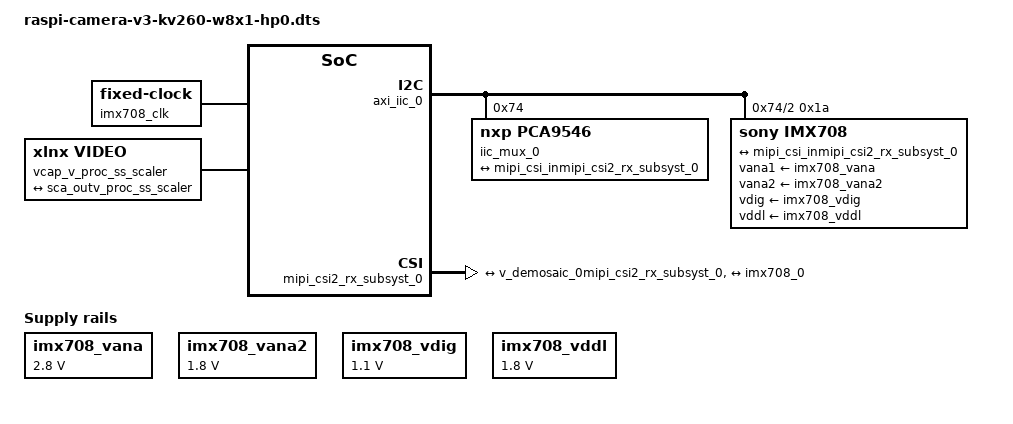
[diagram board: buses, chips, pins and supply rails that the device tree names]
/*
 * CAUTION: This file is automatically generated by Xilinx.
 * Version: XSCT 2022.1
 * Today is: Thu Jul 28 16:23:50 2022
 */


/dts-v1/;
/plugin/;
/ {
	fragment@0 {
		target = <&fpga_full>;
		overlay0: __overlay__ {
			#address-cells = <2>;
			#size-cells = <2>;
			firmware-name = "raspi-camera-v3-kv260-w8x1-hp0.bin";
			resets = <&zynqmp_reset 116>;
		};
	};
	fragment@1 {
		target = <&amba>;
		overlay1: __overlay__ {
			afi0: afi0 {
				compatible = "xlnx,afi-fpga";
				config-afi = < 0 0>, <1 0>, <2 0>, <3 0>, <4 0>, <5 0>, <6 0>, <7 0>, <8 0>, <9 0>, <10 0>, <11 0>, <12 0>, <13 0>, <14 0xa00>, <15 0x000>;
			};
			clocking0: clocking0 {
				#clock-cells = <0>;
				assigned-clock-rates = <99999001>;
				assigned-clocks = <&zynqmp_clk 71>;
				clock-output-names = "fabric_clk";
				clocks = <&zynqmp_clk 71>;
				compatible = "xlnx,fclk";
			};
			clocking1: clocking1 {
				#clock-cells = <0>;
				assigned-clock-rates = <99999001>;
				assigned-clocks = <&zynqmp_clk 72>;
				clock-output-names = "fabric_clk";
				clocks = <&zynqmp_clk 72>;
				compatible = "xlnx,fclk";
			};
		};
	};
	fragment@2 {
		target-path="/";
		overlay2: __overlay__ {
			imx708_vana: fixedregulator0 {
				compatible = "regulator-fixed";
				regulator-name = "imx708_vana";
				regulator-min-microvolt = <2800000>;
				regulator-max-microvolt = <2800000>;
			};
			imx708_vana2: fixedregulator1 {
				compatible = "regulator-fixed";
				regulator-name = "imx708_vana2";
				regulator-min-microvolt = <1800000>;
				regulator-max-microvolt = <1800000>;
			};
			imx708_vdig: fixedregulator2 {
				compatible = "regulator-fixed";
				regulator-name = "imx708_vdig";
				regulator-min-microvolt = <1100000>;
				regulator-max-microvolt = <1100000>;
			};
			imx708_vddl: fixedregulator3 {
				compatible = "regulator-fixed";
				regulator-name = "imx708_vddl";
				regulator-min-microvolt = <1800000>;
				regulator-max-microvolt = <1800000>;
			};
			imx708_clk:camera-clk {
				compatible = "fixed-clock";
				#clock-cells = <0>;
				clock-frequency = <24000000>;
			};
		};
	};
	fragment@3 {
		target = <&amba>;
		overlay3: __overlay__ {
			#address-cells = <2>;
			#size-cells = <2>;
			axi_iic_0: i2c@80030000 {
				#address-cells = <1>;
				#size-cells = <0>;
				clock-names = "s_axi_aclk";
				clocks = <&misc_clk_0>;
				compatible = "xlnx,axi-iic-2.1", "xlnx,xps-iic-2.00.a";
				interrupt-names = "iic2intc_irpt";
				interrupt-parent = <&gic>;
				interrupts = <0 104 4>;
				reg = <0x0 0x80030000 0x0 0x10000>;
				iic_mux_0: i2c_mux@74 { /* u18 */
					compatible = "nxp,pca9546";
					#address-cells = <1>;
					#size-cells = <0>;
					reg = <0x74>;
					isa0_i2c0: i2c@0 {
						reg = <0>;
					};
					isa1_i2c1: i2c@1 {
						reg = <1>;
					};
					rpi_i2c2: i2c@2 {
						#address-cells = <1>;
						#size-cells = <0>;
						reg = <2>;
						imx708: sensor@1a {
							compatible = "sony,imx708";
							reg = <0x1a>;
							clocks = <&imx708_clk>;
							vana1-supply = <&imx708_vana>;   /* 2.8v */
							vana2-supply = <&imx708_vana2>;   /* 1.8v */
							vdig-supply = <&imx708_vdig>;   /* 1.1v */
							vddl-supply = <&imx708_vddl>;   /* 1.8v */
							port {
								imx708_0: endpoint {
									remote-endpoint = <&mipi_csi_inmipi_csi2_rx_subsyst_0>;
									data-lanes = <1 2>;
									clock-noncontinuous;
									link-frequencies = /bits/ 64 <450000000>;
				   				};
							};
						};
					};
				/* Bus 4/4 are not connected */
				};
			};
			misc_clk_0: misc_clk_0 {
				#clock-cells = <0>;
				clock-frequency = <99999000>;
				compatible = "fixed-clock";
			};
			mipi_csi2_rx_subsyst_0: mipi_csi2_rx_subsystem@80002000 {
				clock-names = "dphy_clk_200M", "lite_aclk", "video_aclk";
				clocks = <&misc_clk_1>, <&misc_clk_0>, <&misc_clk_1>;
				compatible = "xlnx,mipi-csi2-rx-subsystem-5.4", "xlnx,mipi-csi2-rx-subsystem-5.0";
				interrupt-names = "csirxss_csi_irq";
				interrupt-parent = <&gic>;
				interrupts = <0 105 4>;
				reg = <0x0 0x80002000 0x0 0x2000>;
				xlnx,axis-tdata-width = <32>;
				xlnx,csi-pxl-format = <0x2b>;
				xlnx,max-lanes = <2>;
				xlnx,ppc = <1>;
				xlnx,vc = <4>;
				xlnx,vfb;
				mipi_csi_portsmipi_csi2_rx_subsyst_0: ports {
					#address-cells = <1>;
					#size-cells = <0>;
					mipi_csi_port1mipi_csi2_rx_subsyst_0: port@1 {
						reg = <1>;
						mipi_csirx_outmipi_csi2_rx_subsyst_0: endpoint {
							remote-endpoint = <&v_demosaic_0mipi_csi2_rx_subsyst_0>;
						};
					};
					mipi_csi_port0mipi_csi2_rx_subsyst_0: port@0 {
						/* User need to add something like remote-endpoint=<&out> under the node csiss_in:endpoint */
						reg = <0>;
						mipi_csi_inmipi_csi2_rx_subsyst_0: endpoint {
							remote-endpoint = <&imx708_0>;
							data-lanes = <1 2>;
						};
					};
				};
			};
			misc_clk_1: misc_clk_1 {
				#clock-cells = <0>;
				clock-frequency = <199998000>;
				compatible = "fixed-clock";
			};
			v_demosaic_0: v_demosaic@a0010000 {
				clock-names = "ap_clk";
				clocks = <&misc_clk_1>;
				compatible = "xlnx,v-demosaic-1.1", "xlnx,v-demosaic";
				interrupt-names = "interrupt";
				interrupt-parent = <&gic>;
				interrupts = <0 106 4>;
				reg = <0x0 0xa0010000 0x0 0x10000>;
				reset-gpios = <&gpio 78 1>;
				xlnx,max-height = <4320>;
				xlnx,max-width = <8192>;
				xlnx,s-axi-ctrl-addr-width = <0x6>;
				xlnx,s-axi-ctrl-data-width = <0x20>;
				demosaic_portsv_demosaic_0: ports {
					#address-cells = <1>;
					#size-cells = <0>;
					demosaic_port1v_demosaic_0: port@1 {
						reg = <1>;
						demo_outv_demosaic_0: endpoint {
							remote-endpoint = <&v_proc_ss_cscv_demosaic_0>;
						};
					};
					demosaic_port0v_demosaic_0: port@0 {
						reg = <0>;
						v_demosaic_0mipi_csi2_rx_subsyst_0: endpoint {
							remote-endpoint = <&mipi_csirx_outmipi_csi2_rx_subsyst_0>;
						};
					};
				};
			};
			v_frmbuf_wr_0: v_frmbuf_wr@a0020000 {
				#dma-cells = <1>;
				clock-names = "ap_clk";
				clocks = <&misc_clk_1>;
				compatible = "xlnx,v-frmbuf-wr-2.5", "xlnx,axi-frmbuf-wr-v2.2";
				interrupt-names = "interrupt";
				interrupt-parent = <&gic>;
				interrupts = <0 108 4>;
				reg = <0x0 0xa0020000 0x0 0x10000>;
				reset-gpios = <&gpio 82 1>;
				xlnx,dma-addr-width = <32>;
				xlnx,dma-align = <8>;
				xlnx,max-height = <4320>;
				xlnx,max-width = <8192>;
				xlnx,pixels-per-clock = <1>;
				xlnx,s-axi-ctrl-addr-width = <0x7>;
				xlnx,s-axi-ctrl-data-width = <0x20>;
				xlnx,vid-formats = "rgb888", "bgr888", "xbgr8888", "xrgb8888", "vuy888", "xvuy8888", "nv12";
				xlnx,video-width = <8>;
			};
			v_gamma_lut_0: v_gamma_lut@a0030000 {
				clock-names = "ap_clk";
				clocks = <&misc_clk_1>;
				compatible = "xlnx,v-gamma-lut-1.1", "xlnx,v-gamma-lut";
				interrupt-names = "interrupt";
				interrupt-parent = <&gic>;
				interrupts = <0 107 4>;
				reg = <0x0 0xa0030000 0x0 0x10000>;
				reset-gpios = <&gpio 79 1>;
				xlnx,max-height = <4320>;
				xlnx,max-width = <8192>;
				xlnx,s-axi-ctrl-addr-width = <13>;
				xlnx,s-axi-ctrl-data-width = <32>;
				gamma_portsv_gamma_lut_0: ports {
					#address-cells = <1>;
					#size-cells = <0>;
					gamma_port1v_gamma_lut_0: port@1 {
						reg = <1>;
						xlnx,video-width  = <10>;
						gamma_outv_gamma_lut_0: endpoint {
							remote-endpoint = <&v_proc_ss_scalerv_gamma_lut_0>;
						};
					};
					gamma_port0v_gamma_lut_0: port@0 {
						reg = <0>;
						xlnx,video-width  = <10>;
						v_gamma_lut_0v_proc_ss_csc: endpoint {
							remote-endpoint = <&csc_outv_proc_ss_csc>;
						};
					};
				};
			};
			v_proc_ss_csc: v_proc_ss_csc@a0040000 {
				clock-names = "aclk";
				clocks = <&misc_clk_1>;
				compatible = "xlnx,v-vpss-csc";
				reg = <0x0 0xa0040000 0x0 0x10000>;
				reset-gpios = <&gpio 80 1>;
				xlnx,colorspace-support = <0>;
				xlnx,csc-enable-window = "true";
				xlnx,max-height = <4320>;
				xlnx,max-width = <8192>;
				xlnx,num-video-components = <3>;
				xlnx,samples-per-clk = <1>;
				xlnx,topology = <3>;
				xlnx,use-uram = <0>;
				xlnx,video-width = <10>;
				csc_portsv_proc_ss_csc: ports {
					#address-cells = <1>;
					#size-cells = <0>;
					csc_port1v_proc_ss_csc: port@1 {
				        /* For xlnx,video-format user needs to fill as per their requirement */
						reg = <1>;
						xlnx,video-format = <3>;
						xlnx,video-width  = <10>;
						csc_outv_proc_ss_csc: endpoint {
							remote-endpoint = <&v_gamma_lut_0v_proc_ss_csc>;
						};
					};
					csc_port0v_proc_ss_csc: port@0 {
				        /* For xlnx,video-format user needs to fill as per their requirement */
						reg = <0>;
						xlnx,video-format = <3>;
						xlnx,video-width  = <10>;
						v_proc_ss_cscv_demosaic_0: endpoint {
							remote-endpoint = <&demo_outv_demosaic_0>;
						};
					};
				};
			};
			v_proc_ss_scaler: v_proc_ss_scaler@a0080000 {
				clock-names = "aclk_axis", "aclk_ctrl";
				clocks = <&misc_clk_1>, <&misc_clk_1>;
				compatible = "xlnx,v-vpss-scaler-2.2";
				reg = <0x0 0xa0080000 0x0 0x40000>;
				reset-gpios = <&gpio 81 1>;
				xlnx,colorspace-support = <0>;
				xlnx,csc-enable-window = "true";
				xlnx,enable-csc = "false";
				xlnx,h-scaler-phases = <64>;
				xlnx,h-scaler-taps = <6>;
				xlnx,max-height = <4320>;
				xlnx,max-num-phases = <64>;
				xlnx,max-width = <8192>;
				xlnx,num-hori-taps = <6>;
				xlnx,num-vert-taps = <6>;
				xlnx,pix-per-clk = <1>;
				xlnx,samples-per-clk = <1>;
				xlnx,scaler-algorithm = <2>;
				xlnx,topology = <0>;
				xlnx,use-uram = <0>;
				xlnx,v-scaler-phases = <64>;
				xlnx,v-scaler-taps = <6>;
				xlnx,video-width = <8>;
				scaler_portsv_proc_ss_scaler: ports {
					#address-cells = <1>;
					#size-cells = <0>;
					scaler_port1v_proc_ss_scaler: port@1 {
					    /* For xlnx,video-format user needs to fill as per their requirement */
						reg = <1>;
						xlnx,video-format = <3>;
						xlnx,video-width  = <8>;
						sca_outv_proc_ss_scaler: endpoint {
							remote-endpoint = <&v_frmbuf_wr_0v_proc_ss_scaler>;
						};
					};
					scaler_port0v_proc_ss_scaler: port@0 {
						/* For xlnx,video-format user needs to fill as per their requirement */
						reg = <0>;
						xlnx,video-format = <3>;
						xlnx,video-width  = <8>;
						v_proc_ss_scalerv_gamma_lut_0: endpoint {
							remote-endpoint = <&gamma_outv_gamma_lut_0>;
						};
					};
				};
			};
			zyxclmm_drm {
				compatible = "xlnx,zocl";
				interrupt-parent = <&gic>;
				interrupts = <0x0 0x89 0x4>, <0x0 0x90 0x4>, <0x0 0x91 0x4>, <0x0 0x92 0x4>, <0x0 0x93 0x4>, <0x0 0x94 0x4>, <0x0 0x95 0x4>, <0x0 0x96 0x4>;
			};
			vcap_v_proc_ss_scaler {
				compatible = "xlnx,video";
				dma-names = "port0";
				dmas = <&v_frmbuf_wr_0 0>;
				vcap_portsv_proc_ss_scaler: ports {
					#address-cells = <1>;
					#size-cells = <0>;
					vcap_portv_proc_ss_scaler: port@0 {
						direction = "input";
						reg = <0>;
						v_frmbuf_wr_0v_proc_ss_scaler: endpoint {
							remote-endpoint = <&sca_outv_proc_ss_scaler>;
						};
					};
				};
			};
		};
	};
};
